AUTOSAR XML (schema 00044)
package /ComponentTypes
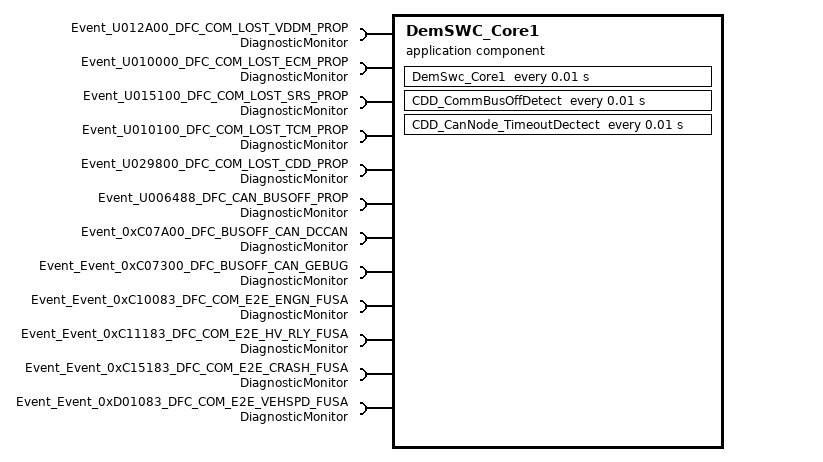
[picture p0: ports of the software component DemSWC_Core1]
  application sw component type DemSWC_Core1
    12 x require port, all with required-interface=DiagnosticMonitor:
      Event_U012A00_DFC_COM_LOST_VDDM_PROP
        required-com-specs:
          SetEventStatus
          ResetEventStatus
          ResetEventDebounceStatus
          SetEventDisabled
          GetEventUdsStatus
          GetEventStatus
          GetEventFailed
          GetEventTested
          GetDTCOfEvent
          GetFaultDetectionCounter
          GetEventFreezeFrameDataEx
          GetEventExtendedDataRecordEx
      Event_U010000_DFC_COM_LOST_ECM_PROP
        required-com-specs:
          SetEventStatus
          ResetEventStatus
          ResetEventDebounceStatus
          SetEventDisabled
          GetEventUdsStatus
          GetEventStatus
          GetEventFailed
          GetEventTested
          GetDTCOfEvent
          GetFaultDetectionCounter
          GetEventFreezeFrameDataEx
          GetEventExtendedDataRecordEx
      Event_U015100_DFC_COM_LOST_SRS_PROP
        required-com-specs:
          SetEventStatus
          ResetEventStatus
          ResetEventDebounceStatus
          SetEventDisabled
          GetEventUdsStatus
          GetEventStatus
          GetEventFailed
          GetEventTested
          GetDTCOfEvent
          GetFaultDetectionCounter
          GetEventFreezeFrameDataEx
          GetEventExtendedDataRecordEx
      Event_U010100_DFC_COM_LOST_TCM_PROP
        required-com-specs:
          SetEventStatus
          ResetEventStatus
          ResetEventDebounceStatus
          SetEventDisabled
          GetEventUdsStatus
          GetEventStatus
          GetEventFailed
          GetEventTested
          GetDTCOfEvent
          GetFaultDetectionCounter
          GetEventFreezeFrameDataEx
          GetEventExtendedDataRecordEx
      Event_U029800_DFC_COM_LOST_CDD_PROP
        required-com-specs:
          SetEventStatus
          ResetEventStatus
          ResetEventDebounceStatus
          SetEventDisabled
          GetEventUdsStatus
          GetEventStatus
          GetEventFailed
          GetEventTested
          GetDTCOfEvent
          GetFaultDetectionCounter
          GetEventFreezeFrameDataEx
          GetEventExtendedDataRecordEx
      Event_U006488_DFC_CAN_BUSOFF_PROP
        required-com-specs:
          SetEventStatus
          ResetEventStatus
          ResetEventDebounceStatus
          SetEventDisabled
          GetEventUdsStatus
          GetEventStatus
          GetEventFailed
          GetEventTested
          GetDTCOfEvent
          GetFaultDetectionCounter
          GetEventFreezeFrameDataEx
          GetEventExtendedDataRecordEx
      Event_0xC07A00_DFC_BUSOFF_CAN_DCCAN
        required-com-specs:
          SetEventStatus
          ResetEventStatus
          ResetEventDebounceStatus
          SetEventDisabled
          GetEventUdsStatus
          GetEventStatus
          GetEventFailed
          GetEventTested
          GetDTCOfEvent
          GetFaultDetectionCounter
          GetEventFreezeFrameDataEx
          GetEventExtendedDataRecordEx
      Event_Event_0xC07300_DFC_BUSOFF_CAN_GEBUG
        required-com-specs:
          SetEventStatus
          ResetEventStatus
          ResetEventDebounceStatus
          SetEventDisabled
          GetEventUdsStatus
          GetEventStatus
          GetEventFailed
          GetEventTested
          GetDTCOfEvent
          GetFaultDetectionCounter
          GetEventFreezeFrameDataEx
          GetEventExtendedDataRecordEx
      Event_Event_0xC10083_DFC_COM_E2E_ENGN_FUSA
        required-com-specs:
          SetEventStatus
          ResetEventStatus
          ResetEventDebounceStatus
          SetEventDisabled
          GetEventUdsStatus
          GetEventStatus
          GetEventFailed
          GetEventTested
          GetDTCOfEvent
          GetFaultDetectionCounter
          GetEventFreezeFrameDataEx
          GetEventExtendedDataRecordEx
      Event_Event_0xC11183_DFC_COM_E2E_HV_RLY_FUSA
        required-com-specs:
          SetEventStatus
          ResetEventStatus
          ResetEventDebounceStatus
          SetEventDisabled
          GetEventUdsStatus
          GetEventStatus
          GetEventFailed
          GetEventTested
          GetDTCOfEvent
          GetFaultDetectionCounter
          GetEventFreezeFrameDataEx
          GetEventExtendedDataRecordEx
      Event_Event_0xC15183_DFC_COM_E2E_CRASH_FUSA
        required-com-specs:
          SetEventStatus
          ResetEventStatus
          ResetEventDebounceStatus
          SetEventDisabled
          GetEventUdsStatus
          GetEventStatus
          GetEventFailed
          GetEventTested
          GetDTCOfEvent
          GetFaultDetectionCounter
          GetEventFreezeFrameDataEx
          GetEventExtendedDataRecordEx
      Event_Event_0xD01083_DFC_COM_E2E_VEHSPD_FUSA
        required-com-specs:
          SetEventStatus
          ResetEventStatus
          ResetEventDebounceStatus
          SetEventDisabled
          GetEventUdsStatus
          GetEventStatus
          GetEventFailed
          GetEventTested
          GetDTCOfEvent
          GetFaultDetectionCounter
          GetEventFreezeFrameDataEx
          GetEventExtendedDataRecordEx
    behavior DemSWC_Core1_InternalBehavior
      timing event TMT_DemSwc_Core1: start-on-event=DemSwc_Core1, period=0.01
      timing event TMT_CDD_CommBusOffDetect: start-on-event=CDD_CommBusOffDetect, period=0.01
      timing event TMT_CDD_CanNode_TimeoutDectect: start-on-event=CDD_CanNode_TimeoutDectect, period=0.01
      runnable DemSwc_Core1
        144 x sync call:
          SC_Event_U006488_Vehicle_Communication_Bus_E_GetDTCOfEvent: operation=Event_U006488_DFC_CAN_BUSOFF_PROP.GetDTCOfEvent
          SC_Event_U006488_Vehicle_Communication_Bus_E_GetEventExtendedDataRecordEx: operation=Event_U006488_DFC_CAN_BUSOFF_PROP.GetEventExtendedDataRecordEx
          SC_Event_U006488_Vehicle_Communication_Bus_E_GetEventFailed: operation=Event_U006488_DFC_CAN_BUSOFF_PROP.GetEventFailed
          SC_Event_U006488_Vehicle_Communication_Bus_E_GetEventFreezeFrameDataEx: operation=Event_U006488_DFC_CAN_BUSOFF_PROP.GetEventFreezeFrameDataEx
          SC_Event_U006488_Vehicle_Communication_Bus_E_GetEventStatus: operation=Event_U006488_DFC_CAN_BUSOFF_PROP.GetEventStatus
          SC_Event_U006488_Vehicle_Communication_Bus_E_GetEventTested: operation=Event_U006488_DFC_CAN_BUSOFF_PROP.GetEventTested
          SC_Event_U006488_Vehicle_Communication_Bus_E_GetEventUdsStatus: operation=Event_U006488_DFC_CAN_BUSOFF_PROP.GetEventUdsStatus
          SC_Event_U006488_Vehicle_Communication_Bus_E_GetFaultDetectionCounter: operation=Event_U006488_DFC_CAN_BUSOFF_PROP.GetFaultDetectionCounter
          SC_Event_U006488_Vehicle_Communication_Bus_E_ResetEventDebounceStatus: operation=Event_U006488_DFC_CAN_BUSOFF_PROP.ResetEventDebounceStatus
          SC_Event_U006488_Vehicle_Communication_Bus_E_ResetEventStatus: operation=Event_U006488_DFC_CAN_BUSOFF_PROP.ResetEventStatus
          SC_Event_U006488_Vehicle_Communication_Bus_E_SetEventDisabled: operation=Event_U006488_DFC_CAN_BUSOFF_PROP.SetEventDisabled
          SC_Event_U006488_Vehicle_Communication_Bus_E_SetEventStatus: operation=Event_U006488_DFC_CAN_BUSOFF_PROP.SetEventStatus
          SC_Event_U010000_Lost_Communication_With_ECM_PCM_A_GetDTCOfEvent: operation=Event_U010000_DFC_COM_LOST_ECM_PROP.GetDTCOfEvent
          SC_Event_U010000_Lost_Communication_With_ECM_PCM_A_GetEventExtendedDataRecordEx: operation=Event_U010000_DFC_COM_LOST_ECM_PROP.GetEventExtendedDataRecordEx
          SC_Event_U010000_Lost_Communication_With_ECM_PCM_A_GetEventFailed: operation=Event_U010000_DFC_COM_LOST_ECM_PROP.GetEventFailed
          SC_Event_U010000_Lost_Communication_With_ECM_PCM_A_GetEventFreezeFrameDataEx: operation=Event_U010000_DFC_COM_LOST_ECM_PROP.GetEventFreezeFrameDataEx
          SC_Event_U010000_Lost_Communication_With_ECM_PCM_A_GetEventStatus: operation=Event_U010000_DFC_COM_LOST_ECM_PROP.GetEventStatus
          SC_Event_U010000_Lost_Communication_With_ECM_PCM_A_GetEventTested: operation=Event_U010000_DFC_COM_LOST_ECM_PROP.GetEventTested
          SC_Event_U010000_Lost_Communication_With_ECM_PCM_A_GetEventUdsStatus: operation=Event_U010000_DFC_COM_LOST_ECM_PROP.GetEventUdsStatus
          SC_Event_U010000_Lost_Communication_With_ECM_PCM_A_GetFaultDetectionCounter: operation=Event_U010000_DFC_COM_LOST_ECM_PROP.GetFaultDetectionCounter
          SC_Event_U010000_Lost_Communication_With_ECM_PCM_A_ResetEventDebounceStatus: operation=Event_U010000_DFC_COM_LOST_ECM_PROP.ResetEventDebounceStatus
          SC_Event_U010000_Lost_Communication_With_ECM_PCM_A_ResetEventStatus: operation=Event_U010000_DFC_COM_LOST_ECM_PROP.ResetEventStatus
          SC_Event_U010000_Lost_Communication_With_ECM_PCM_A_SetEventDisabled: operation=Event_U010000_DFC_COM_LOST_ECM_PROP.SetEventDisabled
          SC_Event_U010000_Lost_Communication_With_ECM_PCM_A_SetEventStatus: operation=Event_U010000_DFC_COM_LOST_ECM_PROP.SetEventStatus
          SC_Event_U010100_Lost_Communication_with_TCM_GetDTCOfEvent: operation=Event_U010100_DFC_COM_LOST_TCM_PROP.GetDTCOfEvent
          SC_Event_U010100_Lost_Communication_with_TCM_GetEventExtendedDataRecordEx: operation=Event_U010100_DFC_COM_LOST_TCM_PROP.GetEventExtendedDataRecordEx
          SC_Event_U010100_Lost_Communication_with_TCM_GetEventFailed: operation=Event_U010100_DFC_COM_LOST_TCM_PROP.GetEventFailed
          SC_Event_U010100_Lost_Communication_with_TCM_GetEventFreezeFrameDataEx: operation=Event_U010100_DFC_COM_LOST_TCM_PROP.GetEventFreezeFrameDataEx
          SC_Event_U010100_Lost_Communication_with_TCM_GetEventStatus: operation=Event_U010100_DFC_COM_LOST_TCM_PROP.GetEventStatus
          SC_Event_U010100_Lost_Communication_with_TCM_GetEventTested: operation=Event_U010100_DFC_COM_LOST_TCM_PROP.GetEventTested
          SC_Event_U010100_Lost_Communication_with_TCM_GetEventUdsStatus: operation=Event_U010100_DFC_COM_LOST_TCM_PROP.GetEventUdsStatus
          SC_Event_U010100_Lost_Communication_with_TCM_GetFaultDetectionCounter: operation=Event_U010100_DFC_COM_LOST_TCM_PROP.GetFaultDetectionCounter
          SC_Event_U010100_Lost_Communication_with_TCM_ResetEventDebounceStatus: operation=Event_U010100_DFC_COM_LOST_TCM_PROP.ResetEventDebounceStatus
          SC_Event_U010100_Lost_Communication_with_TCM_ResetEventStatus: operation=Event_U010100_DFC_COM_LOST_TCM_PROP.ResetEventStatus
          SC_Event_U010100_Lost_Communication_with_TCM_SetEventDisabled: operation=Event_U010100_DFC_COM_LOST_TCM_PROP.SetEventDisabled
          SC_Event_U010100_Lost_Communication_with_TCM_SetEventStatus: operation=Event_U010100_DFC_COM_LOST_TCM_PROP.SetEventStatus
          SC_Event_U012A00_Lost_Communication_With_Chassis_Control_Module_A_GetDTCOfEvent: operation=Event_U012A00_DFC_COM_LOST_VDDM_PROP.GetDTCOfEvent
          SC_Event_U012A00_Lost_Communication_With_Chassis_Control_Module_A_GetEventExtendedDataRecordEx: operation=Event_U012A00_DFC_COM_LOST_VDDM_PROP.GetEventExtendedDataRecordEx
          SC_Event_U012A00_Lost_Communication_With_Chassis_Control_Module_A_GetEventFailed: operation=Event_U012A00_DFC_COM_LOST_VDDM_PROP.GetEventFailed
          SC_Event_U012A00_Lost_Communication_With_Chassis_Control_Module_A_GetEventFreezeFrameDataEx: operation=Event_U012A00_DFC_COM_LOST_VDDM_PROP.GetEventFreezeFrameDataEx
          SC_Event_U012A00_Lost_Communication_With_Chassis_Control_Module_A_GetEventStatus: operation=Event_U012A00_DFC_COM_LOST_VDDM_PROP.GetEventStatus
          SC_Event_U012A00_Lost_Communication_With_Chassis_Control_Module_A_GetEventTested: operation=Event_U012A00_DFC_COM_LOST_VDDM_PROP.GetEventTested
          SC_Event_U012A00_Lost_Communication_With_Chassis_Control_Module_A_GetEventUdsStatus: operation=Event_U012A00_DFC_COM_LOST_VDDM_PROP.GetEventUdsStatus
          SC_Event_U012A00_Lost_Communication_With_Chassis_Control_Module_A_GetFaultDetectionCounter: operation=Event_U012A00_DFC_COM_LOST_VDDM_PROP.GetFaultDetectionCounter
          SC_Event_U012A00_Lost_Communication_With_Chassis_Control_Module_A_ResetEventDebounceStatus: operation=Event_U012A00_DFC_COM_LOST_VDDM_PROP.ResetEventDebounceStatus
          SC_Event_U012A00_Lost_Communication_With_Chassis_Control_Module_A_ResetEventStatus: operation=Event_U012A00_DFC_COM_LOST_VDDM_PROP.ResetEventStatus
          SC_Event_U012A00_Lost_Communication_With_Chassis_Control_Module_A_SetEventDisabled: operation=Event_U012A00_DFC_COM_LOST_VDDM_PROP.SetEventDisabled
          SC_Event_U012A00_Lost_Communication_With_Chassis_Control_Module_A_SetEventStatus: operation=Event_U012A00_DFC_COM_LOST_VDDM_PROP.SetEventStatus
          SC_Event_U015100_Lost_Communication_With_Restraints_Control_Module_GetDTCOfEvent: operation=Event_U015100_DFC_COM_LOST_SRS_PROP.GetDTCOfEvent
          SC_Event_U015100_Lost_Communication_With_Restraints_Control_Module_GetEventExtendedDataRecordEx: operation=Event_U015100_DFC_COM_LOST_SRS_PROP.GetEventExtendedDataRecordEx
          SC_Event_U015100_Lost_Communication_With_Restraints_Control_Module_GetEventFailed: operation=Event_U015100_DFC_COM_LOST_SRS_PROP.GetEventFailed
          SC_Event_U015100_Lost_Communication_With_Restraints_Control_Module_GetEventFreezeFrameDataEx: operation=Event_U015100_DFC_COM_LOST_SRS_PROP.GetEventFreezeFrameDataEx
          SC_Event_U015100_Lost_Communication_With_Restraints_Control_Module_GetEventStatus: operation=Event_U015100_DFC_COM_LOST_SRS_PROP.GetEventStatus
          SC_Event_U015100_Lost_Communication_With_Restraints_Control_Module_GetEventTested: operation=Event_U015100_DFC_COM_LOST_SRS_PROP.GetEventTested
          SC_Event_U015100_Lost_Communication_With_Restraints_Control_Module_GetEventUdsStatus: operation=Event_U015100_DFC_COM_LOST_SRS_PROP.GetEventUdsStatus
          SC_Event_U015100_Lost_Communication_With_Restraints_Control_Module_GetFaultDetectionCounter: operation=Event_U015100_DFC_COM_LOST_SRS_PROP.GetFaultDetectionCounter
          SC_Event_U015100_Lost_Communication_With_Restraints_Control_Module_ResetEventDebounceStatus: operation=Event_U015100_DFC_COM_LOST_SRS_PROP.ResetEventDebounceStatus
          SC_Event_U015100_Lost_Communication_With_Restraints_Control_Module_ResetEventStatus: operation=Event_U015100_DFC_COM_LOST_SRS_PROP.ResetEventStatus
          SC_Event_U015100_Lost_Communication_With_Restraints_Control_Module_SetEventDisabled: operation=Event_U015100_DFC_COM_LOST_SRS_PROP.SetEventDisabled
          SC_Event_U015100_Lost_Communication_With_Restraints_Control_Module_SetEventStatus: operation=Event_U015100_DFC_COM_LOST_SRS_PROP.SetEventStatus
          SC_Event_U029800_Lost_Communication_With_DC_DC_Converter_Control_Module_A_GetDTCOfEvent: operation=Event_U029800_DFC_COM_LOST_CDD_PROP.GetDTCOfEvent
          SC_Event_U029800_Lost_Communication_With_DC_DC_Converter_Control_Module_A_GetEventExtendedDataRecordEx: operation=Event_U029800_DFC_COM_LOST_CDD_PROP.GetEventExtendedDataRecordEx
          SC_Event_U029800_Lost_Communication_With_DC_DC_Converter_Control_Module_A_GetEventFailed: operation=Event_U029800_DFC_COM_LOST_CDD_PROP.GetEventFailed
          SC_Event_U029800_Lost_Communication_With_DC_DC_Converter_Control_Module_A_GetEventFreezeFrameDataEx: operation=Event_U029800_DFC_COM_LOST_CDD_PROP.GetEventFreezeFrameDataEx
          SC_Event_U029800_Lost_Communication_With_DC_DC_Converter_Control_Module_A_GetEventStatus: operation=Event_U029800_DFC_COM_LOST_CDD_PROP.GetEventStatus
          SC_Event_U029800_Lost_Communication_With_DC_DC_Converter_Control_Module_A_GetEventTested: operation=Event_U029800_DFC_COM_LOST_CDD_PROP.GetEventTested
          SC_Event_U029800_Lost_Communication_With_DC_DC_Converter_Control_Module_A_GetEventUdsStatus: operation=Event_U029800_DFC_COM_LOST_CDD_PROP.GetEventUdsStatus
          SC_Event_U029800_Lost_Communication_With_DC_DC_Converter_Control_Module_A_GetFaultDetectionCounter: operation=Event_U029800_DFC_COM_LOST_CDD_PROP.GetFaultDetectionCounter
          SC_Event_U029800_Lost_Communication_With_DC_DC_Converter_Control_Module_A_ResetEventDebounceStatus: operation=Event_U029800_DFC_COM_LOST_CDD_PROP.ResetEventDebounceStatus
          SC_Event_U029800_Lost_Communication_With_DC_DC_Converter_Control_Module_A_ResetEventStatus: operation=Event_U029800_DFC_COM_LOST_CDD_PROP.ResetEventStatus
          SC_Event_U029800_Lost_Communication_With_DC_DC_Converter_Control_Module_A_SetEventDisabled: operation=Event_U029800_DFC_COM_LOST_CDD_PROP.SetEventDisabled
          SC_Event_U029800_Lost_Communication_With_DC_DC_Converter_Control_Module_A_SetEventStatus: operation=Event_U029800_DFC_COM_LOST_CDD_PROP.SetEventStatus
          SC_Event_0xC07A00_DFC_BUSOFF_CAN_DCCAN_GetDTCOfEvent: operation=Event_0xC07A00_DFC_BUSOFF_CAN_DCCAN.GetDTCOfEvent
          SC_Event_0xC07A00_DFC_BUSOFF_CAN_DCCAN_GetEventExtendedDataRecordEx: operation=Event_0xC07A00_DFC_BUSOFF_CAN_DCCAN.GetEventExtendedDataRecordEx
          SC_Event_0xC07A00_DFC_BUSOFF_CAN_DCCAN_GetEventFailed: operation=Event_0xC07A00_DFC_BUSOFF_CAN_DCCAN.GetEventFailed
          SC_Event_0xC07A00_DFC_BUSOFF_CAN_DCCAN_GetEventFreezeFrameDataEx: operation=Event_0xC07A00_DFC_BUSOFF_CAN_DCCAN.GetEventFreezeFrameDataEx
          SC_Event_0xC07A00_DFC_BUSOFF_CAN_DCCAN_GetEventStatus: operation=Event_0xC07A00_DFC_BUSOFF_CAN_DCCAN.GetEventStatus
          SC_Event_0xC07A00_DFC_BUSOFF_CAN_DCCAN_GetEventTested: operation=Event_0xC07A00_DFC_BUSOFF_CAN_DCCAN.GetEventTested
          SC_Event_0xC07A00_DFC_BUSOFF_CAN_DCCAN_GetEventUdsStatus: operation=Event_0xC07A00_DFC_BUSOFF_CAN_DCCAN.GetEventUdsStatus
          SC_Event_0xC07A00_DFC_BUSOFF_CAN_DCCAN_GetFaultDetectionCounter: operation=Event_0xC07A00_DFC_BUSOFF_CAN_DCCAN.GetFaultDetectionCounter
          SC_Event_0xC07A00_DFC_BUSOFF_CAN_DCCAN_ResetEventDebounceStatus: operation=Event_0xC07A00_DFC_BUSOFF_CAN_DCCAN.ResetEventDebounceStatus
          SC_Event_0xC07A00_DFC_BUSOFF_CAN_DCCAN_ResetEventStatus: operation=Event_0xC07A00_DFC_BUSOFF_CAN_DCCAN.ResetEventStatus
          SC_Event_0xC07A00_DFC_BUSOFF_CAN_DCCAN_SetEventDisabled: operation=Event_0xC07A00_DFC_BUSOFF_CAN_DCCAN.SetEventDisabled
          SC_Event_0xC07A00_DFC_BUSOFF_CAN_DCCAN_SetEventStatus: operation=Event_0xC07A00_DFC_BUSOFF_CAN_DCCAN.SetEventStatus
          SC_Event_Event_0xC07300_DFC_BUSOFF_CAN_GEBUG_GetDTCOfEvent: operation=Event_Event_0xC07300_DFC_BUSOFF_CAN_GEBUG.GetDTCOfEvent
          SC_Event_Event_0xC07300_DFC_BUSOFF_CAN_GEBUG_GetEventExtendedDataRecordEx: operation=Event_Event_0xC07300_DFC_BUSOFF_CAN_GEBUG.GetEventExtendedDataRecordEx
          SC_Event_Event_0xC07300_DFC_BUSOFF_CAN_GEBUG_GetEventFailed: operation=Event_Event_0xC07300_DFC_BUSOFF_CAN_GEBUG.GetEventFailed
          SC_Event_Event_0xC07300_DFC_BUSOFF_CAN_GEBUG_GetEventFreezeFrameDataEx: operation=Event_Event_0xC07300_DFC_BUSOFF_CAN_GEBUG.GetEventFreezeFrameDataEx
          SC_Event_Event_0xC07300_DFC_BUSOFF_CAN_GEBUG_GetEventStatus: operation=Event_Event_0xC07300_DFC_BUSOFF_CAN_GEBUG.GetEventStatus
          SC_Event_Event_0xC07300_DFC_BUSOFF_CAN_GEBUG_GetEventTested: operation=Event_Event_0xC07300_DFC_BUSOFF_CAN_GEBUG.GetEventTested
          SC_Event_Event_0xC07300_DFC_BUSOFF_CAN_GEBUG_GetEventUdsStatus: operation=Event_Event_0xC07300_DFC_BUSOFF_CAN_GEBUG.GetEventUdsStatus
          SC_Event_Event_0xC07300_DFC_BUSOFF_CAN_GEBUG_GetFaultDetectionCounter: operation=Event_Event_0xC07300_DFC_BUSOFF_CAN_GEBUG.GetFaultDetectionCounter
          SC_Event_Event_0xC07300_DFC_BUSOFF_CAN_GEBUG_ResetEventDebounceStatus: operation=Event_Event_0xC07300_DFC_BUSOFF_CAN_GEBUG.ResetEventDebounceStatus
          SC_Event_Event_0xC07300_DFC_BUSOFF_CAN_GEBUG_ResetEventStatus: operation=Event_Event_0xC07300_DFC_BUSOFF_CAN_GEBUG.ResetEventStatus
          SC_Event_Event_0xC07300_DFC_BUSOFF_CAN_GEBUG_SetEventDisabled: operation=Event_Event_0xC07300_DFC_BUSOFF_CAN_GEBUG.SetEventDisabled
          SC_Event_Event_0xC07300_DFC_BUSOFF_CAN_GEBUG_SetEventStatus: operation=Event_Event_0xC07300_DFC_BUSOFF_CAN_GEBUG.SetEventStatus
          SC_Event_Event_0xC10083_DFC_COM_E2E_ENGN_FUSA_GetDTCOfEvent: operation=Event_Event_0xC10083_DFC_COM_E2E_ENGN_FUSA.GetDTCOfEvent
          SC_Event_Event_0xC10083_DFC_COM_E2E_ENGN_FUSA_GetEventExtendedDataRecordEx: operation=Event_Event_0xC10083_DFC_COM_E2E_ENGN_FUSA.GetEventExtendedDataRecordEx
          SC_Event_Event_0xC10083_DFC_COM_E2E_ENGN_FUSA_GetEventFailed: operation=Event_Event_0xC10083_DFC_COM_E2E_ENGN_FUSA.GetEventFailed
          SC_Event_Event_0xC10083_DFC_COM_E2E_ENGN_FUSA_GetEventFreezeFrameDataEx: operation=Event_Event_0xC10083_DFC_COM_E2E_ENGN_FUSA.GetEventFreezeFrameDataEx
          SC_Event_Event_0xC10083_DFC_COM_E2E_ENGN_FUSA_GetEventStatus: operation=Event_Event_0xC10083_DFC_COM_E2E_ENGN_FUSA.GetEventStatus
          SC_Event_Event_0xC10083_DFC_COM_E2E_ENGN_FUSA_GetEventTested: operation=Event_Event_0xC10083_DFC_COM_E2E_ENGN_FUSA.GetEventTested
          SC_Event_Event_0xC10083_DFC_COM_E2E_ENGN_FUSA_GetEventUdsStatus: operation=Event_Event_0xC10083_DFC_COM_E2E_ENGN_FUSA.GetEventUdsStatus
          SC_Event_Event_0xC10083_DFC_COM_E2E_ENGN_FUSA_GetFaultDetectionCounter: operation=Event_Event_0xC10083_DFC_COM_E2E_ENGN_FUSA.GetFaultDetectionCounter
          SC_Event_Event_0xC10083_DFC_COM_E2E_ENGN_FUSA_ResetEventDebounceStatus: operation=Event_Event_0xC10083_DFC_COM_E2E_ENGN_FUSA.ResetEventDebounceStatus
          SC_Event_Event_0xC10083_DFC_COM_E2E_ENGN_FUSA_ResetEventStatus: operation=Event_Event_0xC10083_DFC_COM_E2E_ENGN_FUSA.ResetEventStatus
          SC_Event_Event_0xC10083_DFC_COM_E2E_ENGN_FUSA_SetEventDisabled: operation=Event_Event_0xC10083_DFC_COM_E2E_ENGN_FUSA.SetEventDisabled
          SC_Event_Event_0xC10083_DFC_COM_E2E_ENGN_FUSA_SetEventStatus: operation=Event_Event_0xC10083_DFC_COM_E2E_ENGN_FUSA.SetEventStatus
          SC_Event_Event_0xC11183_DFC_COM_E2E_HV_RLY_FUSA_GetDTCOfEvent: operation=Event_Event_0xC11183_DFC_COM_E2E_HV_RLY_FUSA.GetDTCOfEvent
          SC_Event_Event_0xC11183_DFC_COM_E2E_HV_RLY_FUSA_GetEventExtendedDataRecordEx: operation=Event_Event_0xC11183_DFC_COM_E2E_HV_RLY_FUSA.GetEventExtendedDataRecordEx
          SC_Event_Event_0xC11183_DFC_COM_E2E_HV_RLY_FUSA_GetEventFailed: operation=Event_Event_0xC11183_DFC_COM_E2E_HV_RLY_FUSA.GetEventFailed
          SC_Event_Event_0xC11183_DFC_COM_E2E_HV_RLY_FUSA_GetEventFreezeFrameDataEx: operation=Event_Event_0xC11183_DFC_COM_E2E_HV_RLY_FUSA.GetEventFreezeFrameDataEx
          SC_Event_Event_0xC11183_DFC_COM_E2E_HV_RLY_FUSA_GetEventStatus: operation=Event_Event_0xC11183_DFC_COM_E2E_HV_RLY_FUSA.GetEventStatus
          SC_Event_Event_0xC11183_DFC_COM_E2E_HV_RLY_FUSA_GetEventTested: operation=Event_Event_0xC11183_DFC_COM_E2E_HV_RLY_FUSA.GetEventTested
          SC_Event_Event_0xC11183_DFC_COM_E2E_HV_RLY_FUSA_GetEventUdsStatus: operation=Event_Event_0xC11183_DFC_COM_E2E_HV_RLY_FUSA.GetEventUdsStatus
          SC_Event_Event_0xC11183_DFC_COM_E2E_HV_RLY_FUSA_GetFaultDetectionCounter: operation=Event_Event_0xC11183_DFC_COM_E2E_HV_RLY_FUSA.GetFaultDetectionCounter
          SC_Event_Event_0xC11183_DFC_COM_E2E_HV_RLY_FUSA_ResetEventDebounceStatus: operation=Event_Event_0xC11183_DFC_COM_E2E_HV_RLY_FUSA.ResetEventDebounceStatus
          SC_Event_Event_0xC11183_DFC_COM_E2E_HV_RLY_FUSA_ResetEventStatus: operation=Event_Event_0xC11183_DFC_COM_E2E_HV_RLY_FUSA.ResetEventStatus
          SC_Event_Event_0xC11183_DFC_COM_E2E_HV_RLY_FUSA_SetEventDisabled: operation=Event_Event_0xC11183_DFC_COM_E2E_HV_RLY_FUSA.SetEventDisabled
          SC_Event_Event_0xC11183_DFC_COM_E2E_HV_RLY_FUSA_SetEventStatus: operation=Event_Event_0xC11183_DFC_COM_E2E_HV_RLY_FUSA.SetEventStatus
          SC_Event_Event_0xC15183_DFC_COM_E2E_CRASH_FUSA_GetDTCOfEvent: operation=Event_Event_0xC15183_DFC_COM_E2E_CRASH_FUSA.GetDTCOfEvent
          SC_Event_Event_0xC15183_DFC_COM_E2E_CRASH_FUSA_GetEventExtendedDataRecordEx: operation=Event_Event_0xC15183_DFC_COM_E2E_CRASH_FUSA.GetEventExtendedDataRecordEx
          SC_Event_Event_0xC15183_DFC_COM_E2E_CRASH_FUSA_GetEventFailed: operation=Event_Event_0xC15183_DFC_COM_E2E_CRASH_FUSA.GetEventFailed
          SC_Event_Event_0xC15183_DFC_COM_E2E_CRASH_FUSA_GetEventFreezeFrameDataEx: operation=Event_Event_0xC15183_DFC_COM_E2E_CRASH_FUSA.GetEventFreezeFrameDataEx
          SC_Event_Event_0xC15183_DFC_COM_E2E_CRASH_FUSA_GetEventStatus: operation=Event_Event_0xC15183_DFC_COM_E2E_CRASH_FUSA.GetEventStatus
          SC_Event_Event_0xC15183_DFC_COM_E2E_CRASH_FUSA_GetEventTested: operation=Event_Event_0xC15183_DFC_COM_E2E_CRASH_FUSA.GetEventTested
          SC_Event_Event_0xC15183_DFC_COM_E2E_CRASH_FUSA_GetEventUdsStatus: operation=Event_Event_0xC15183_DFC_COM_E2E_CRASH_FUSA.GetEventUdsStatus
          SC_Event_Event_0xC15183_DFC_COM_E2E_CRASH_FUSA_GetFaultDetectionCounter: operation=Event_Event_0xC15183_DFC_COM_E2E_CRASH_FUSA.GetFaultDetectionCounter
          SC_Event_Event_0xC15183_DFC_COM_E2E_CRASH_FUSA_ResetEventDebounceStatus: operation=Event_Event_0xC15183_DFC_COM_E2E_CRASH_FUSA.ResetEventDebounceStatus
          SC_Event_Event_0xC15183_DFC_COM_E2E_CRASH_FUSA_ResetEventStatus: operation=Event_Event_0xC15183_DFC_COM_E2E_CRASH_FUSA.ResetEventStatus
          SC_Event_Event_0xC15183_DFC_COM_E2E_CRASH_FUSA_SetEventDisabled: operation=Event_Event_0xC15183_DFC_COM_E2E_CRASH_FUSA.SetEventDisabled
          SC_Event_Event_0xC15183_DFC_COM_E2E_CRASH_FUSA_SetEventStatus: operation=Event_Event_0xC15183_DFC_COM_E2E_CRASH_FUSA.SetEventStatus
          SC_Event_Event_0xD01083_DFC_COM_E2E_VEHSPD_FUSA_GetDTCOfEvent: operation=Event_Event_0xD01083_DFC_COM_E2E_VEHSPD_FUSA.GetDTCOfEvent
          SC_Event_Event_0xD01083_DFC_COM_E2E_VEHSPD_FUSA_GetEventExtendedDataRecordEx: operation=Event_Event_0xD01083_DFC_COM_E2E_VEHSPD_FUSA.GetEventExtendedDataRecordEx
          SC_Event_Event_0xD01083_DFC_COM_E2E_VEHSPD_FUSA_GetEventFailed: operation=Event_Event_0xD01083_DFC_COM_E2E_VEHSPD_FUSA.GetEventFailed
          SC_Event_Event_0xD01083_DFC_COM_E2E_VEHSPD_FUSA_GetEventFreezeFrameDataEx: operation=Event_Event_0xD01083_DFC_COM_E2E_VEHSPD_FUSA.GetEventFreezeFrameDataEx
          SC_Event_Event_0xD01083_DFC_COM_E2E_VEHSPD_FUSA_GetEventStatus: operation=Event_Event_0xD01083_DFC_COM_E2E_VEHSPD_FUSA.GetEventStatus
          SC_Event_Event_0xD01083_DFC_COM_E2E_VEHSPD_FUSA_GetEventTested: operation=Event_Event_0xD01083_DFC_COM_E2E_VEHSPD_FUSA.GetEventTested
          SC_Event_Event_0xD01083_DFC_COM_E2E_VEHSPD_FUSA_GetEventUdsStatus: operation=Event_Event_0xD01083_DFC_COM_E2E_VEHSPD_FUSA.GetEventUdsStatus
          SC_Event_Event_0xD01083_DFC_COM_E2E_VEHSPD_FUSA_GetFaultDetectionCounter: operation=Event_Event_0xD01083_DFC_COM_E2E_VEHSPD_FUSA.GetFaultDetectionCounter
          SC_Event_Event_0xD01083_DFC_COM_E2E_VEHSPD_FUSA_ResetEventDebounceStatus: operation=Event_Event_0xD01083_DFC_COM_E2E_VEHSPD_FUSA.ResetEventDebounceStatus
          SC_Event_Event_0xD01083_DFC_COM_E2E_VEHSPD_FUSA_ResetEventStatus: operation=Event_Event_0xD01083_DFC_COM_E2E_VEHSPD_FUSA.ResetEventStatus
          SC_Event_Event_0xD01083_DFC_COM_E2E_VEHSPD_FUSA_SetEventDisabled: operation=Event_Event_0xD01083_DFC_COM_E2E_VEHSPD_FUSA.SetEventDisabled
          SC_Event_Event_0xD01083_DFC_COM_E2E_VEHSPD_FUSA_SetEventStatus: operation=Event_Event_0xD01083_DFC_COM_E2E_VEHSPD_FUSA.SetEventStatus
      runnable CDD_CommBusOffDetect
      runnable CDD_CanNode_TimeoutDectect
  swc implementation DemSWC_Core1_Implementation: behavior=DemSWC_Core1_InternalBehavior
    code-descriptors:
      code Default: artifact-descriptors=autosar-engineering-object=category=SWSRC
